VERSION ""

NS_ :

BS_:

BU_:

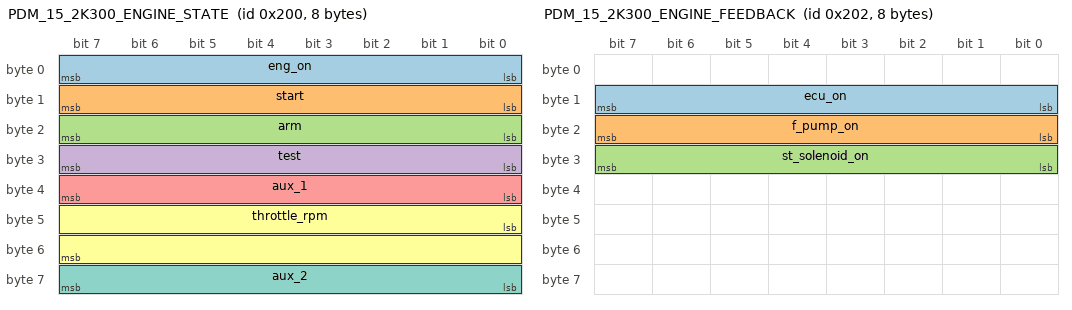
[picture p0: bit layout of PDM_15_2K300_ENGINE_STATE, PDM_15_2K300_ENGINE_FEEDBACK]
BO_ 512 PDM_15_2K300_ENGINE_STATE: 8 Vector__XXX
 SG_ eng_on : 0|8@1+ (1,0) [0|0] "" Vector__XXX
 SG_ start : 8|8@1+ (1,0) [0|0] "" Vector__XXX
 SG_ arm : 16|8@1+ (1,0) [0|0] "" Vector__XXX
 SG_ test : 24|8@1+ (1,0) [0|0] "" Vector__XXX
 SG_ aux_1 : 32|8@1+ (1,0) [0|0] "" Vector__XXX
 SG_ throttle_rpm : 40|16@1+ (1,0) [0|0] "" Vector__XXX
 SG_ aux_2 : 56|8@1+ (1,0) [0|0] "" Vector__XXX

BO_ 514 PDM_15_2K300_ENGINE_FEEDBACK: 8 Vector__XXX
 SG_ ecu_on : 8|8@1+ (1,0) [0|0] "" Vector__XXX
 SG_ f_pump_on : 16|8@1+ (1,0) [0|0] "" Vector__XXX
 SG_ st_solenoid_on : 24|8@1+ (1,0) [0|0] "" Vector__XXX

VAL_ 0 CS 1 "Start" 2 "Stop" 128 "EnterPreOperational" 129 "ResetNode" 130 "ResetCommunication" ;

CM_ SG_ 512 throttle_rpm "RPM multiplied by 8";
